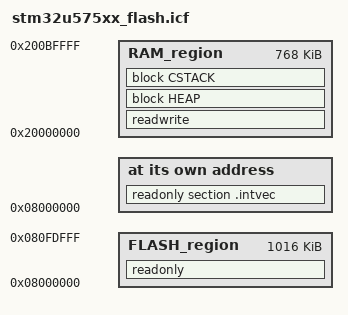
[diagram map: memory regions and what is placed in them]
/**********************************************************************************/
/**** Linker File (ICF) handled by STM32CubeMX/ProjectGenerator, don't touch ! ****/
/**********************************************************************************/

/*-Sizes-*/
define symbol __intvect_start__ = 0x08000000;

define symbol __stack_size__ = 0x7000;
define symbol __heap_size__  = 0x6000;

define symbol __region_RAM_start__   = 0x20000000;
define symbol __region_RAM_end__     = 0x200BFFFF;
define symbol __region_FLASH_start__ = 0x08000000;
define symbol __region_FLASH_end__   = 0x80FDFFF;

/*--------------------------------------------------------------------------------*/

/*-Memory Regions-*/
define memory mem with size = 4G;
define region RAM_region   = mem:[from __region_RAM_start__   to __region_RAM_end__];
define region FLASH_region = mem:[from __region_FLASH_start__ to __region_FLASH_end__];

/*-Blocks-*/
define block CSTACK with alignment = 8, size = __stack_size__ {};
define block HEAP   with alignment = 8, size = __heap_size__  {};

/*-Initialization strategies-*/
initialize by copy { readwrite };
do not initialize  { section .noinit };

/*-Sections placements-*/
place at address mem:__intvect_start__ { readonly section .intvec };

place in FLASH_region  { readonly };
place in RAM_region  { readwrite, block HEAP, block CSTACK };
